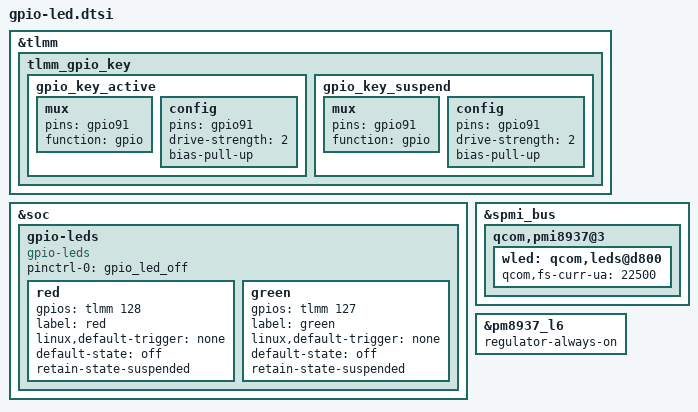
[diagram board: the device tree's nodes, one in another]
/* Copyright (c) 2015, The Linux Foundation. All rights reserved.
 *
 * This program is free software; you can redistribute it and/or modify
 * it under the terms of the GNU General Public License version 2 and
 * only version 2 as published by the Free Software Foundation.
 *
 * This program is distributed in the hope that it will be useful,
 * but WITHOUT ANY WARRANTY; without even the implied warranty of
 * MERCHANTABILITY or FITNESS FOR A PARTICULAR PURPOSE.  See the
 * GNU General Public License for more details.
 */

/* three color led device node */
&tlmm {
		tlmm_gpio_key {
			gpio_key_active: gpio_key_active {
				mux {
					pins = "gpio91";
					function = "gpio";
				};

				config {
					pins = "gpio91";
					drive-strength = <2>;
					bias-pull-up;
				};
			};

			gpio_key_suspend: gpio_key_suspend {
				mux {
					pins = "gpio91";
					function = "gpio";
				};

				config {
					pins = "gpio91";
					drive-strength = <2>;
					bias-pull-up;
				};
			};
		};
};
&soc {
	gpio-leds {
		compatible = "gpio-leds";
		status = "okay";
		pinctrl-names = "default";
		pinctrl-0 = <&gpio_led_off>;

		red {
			gpios = <&tlmm 128 0>;
			label = "red";
			linux,default-trigger = "none";
			default-state = "off";
			retain-state-suspended;
		};

		green {
			gpios = <&tlmm 127 0>;
			label = "green";
			linux,default-trigger = "none";
			default-state = "off";
			retain-state-suspended;
		};

	};
};

&spmi_bus {
	qcom,pmi8937@3 {
		wled: qcom,leds@d800 {
			qcom,fs-curr-ua = <22500>;
		};
	};
};

&pm8937_l6 {
        regulator-always-on;
};

/*
&pm8937_l8 {
        regulator-min-microvolt = <2850000>;
};
*/
